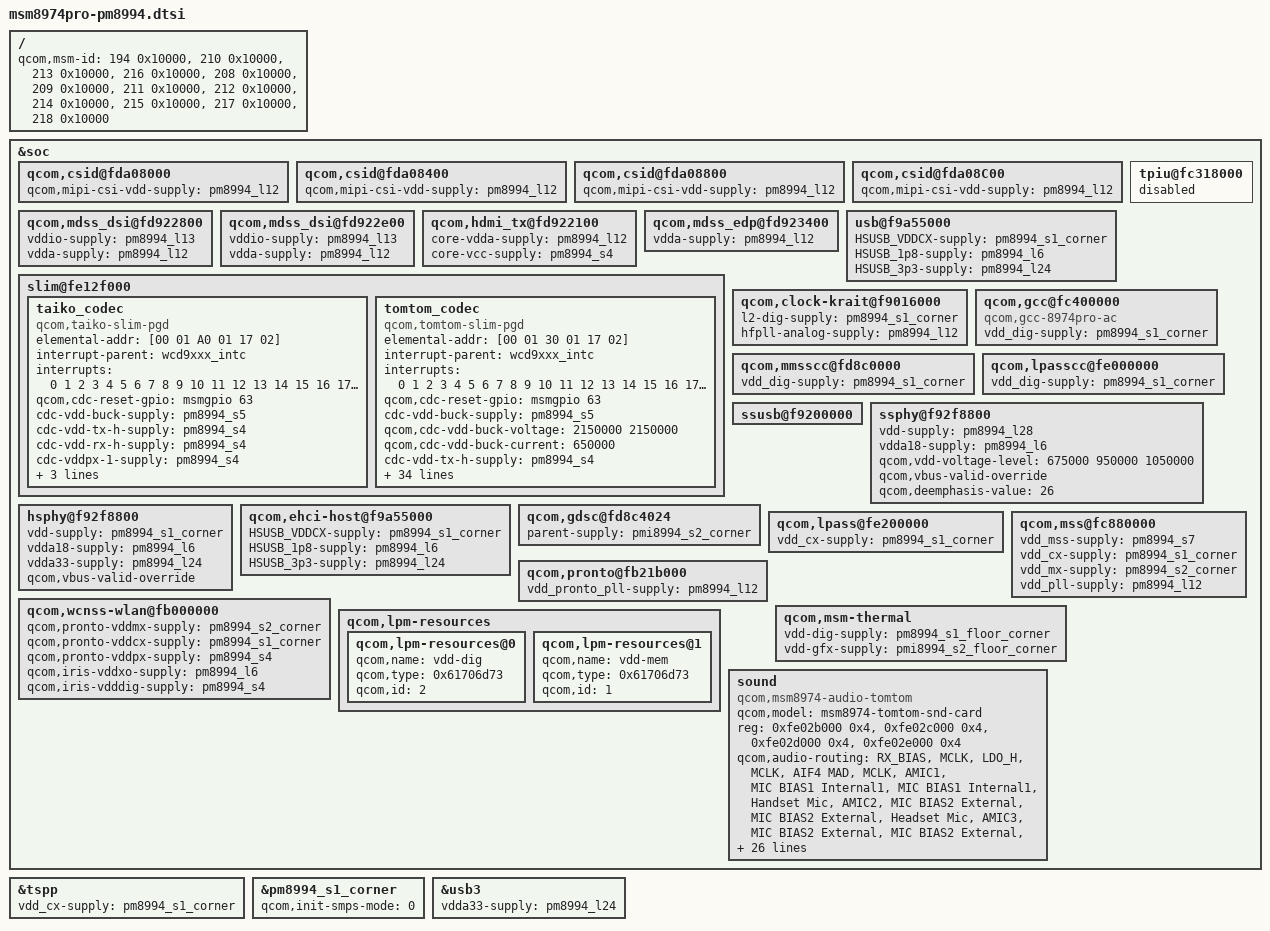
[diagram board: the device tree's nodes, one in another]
/* Copyright (c) 2013-2015, The Linux Foundation. All rights reserved.
 *
 * This program is free software; you can redistribute it and/or modify
 * it under the terms of the GNU General Public License version 2 and
 * only version 2 as published by the Free Software Foundation.
 *
 * This program is distributed in the hope that it will be useful,
 * but WITHOUT ANY WARRANTY; without even the implied warranty of
 * MERCHANTABILITY or FITNESS FOR A PARTICULAR PURPOSE.  See the
 * GNU General Public License for more details.
 */

/*
 * As a general rule, only chipset-specific property overrides should be placed
 * inside this file. However, device definitions should be placed inside the
 * msm8974.dtsi / msm8974pro.dtsi file(s).
 */

#include "msm8974pro.dtsi"
#include "msm-pm8994.dtsi"
#include "msm-pmi8994.dtsi"
#include "msm-pm8994-rpm-regulator.dtsi"
#include "msm8994-regulator.dtsi"

/ {
	qcom,msm-id = <194 0x10000>,
		      <210 0x10000>,
		      <213 0x10000>,
		      <216 0x10000>,
		      <208 0x10000>,
		      <209 0x10000>,
		      <211 0x10000>,
		      <212 0x10000>,
		      <214 0x10000>,
		      <215 0x10000>,
		      <217 0x10000>,
		      <218 0x10000>;
};

/*
 * Override PM8841 and PM8941 resources with proper PM8994 resources for
 * MSM8994 Interposer.
 */

&soc {
	qcom,csid@fda08000  {
		qcom,mipi-csi-vdd-supply = <&pm8994_l12>;
	};

	qcom,csid@fda08400 {
		qcom,mipi-csi-vdd-supply = <&pm8994_l12>;
	};

	qcom,csid@fda08800 {
		qcom,mipi-csi-vdd-supply = <&pm8994_l12>;
	};

	qcom,csid@fda08C00 {
		qcom,mipi-csi-vdd-supply = <&pm8994_l12>;
	};

	tpiu@fc318000 {
		status = "disabled";
		/delete-property/ vdd-supply;
		/delete-property/ vdd-io-supply;
	};

	qcom,mdss_dsi@fd922800 {
		vddio-supply = <&pm8994_l13>;
		vdda-supply = <&pm8994_l12>;
		/delete-property/ qcom,platform-reset-gpio;
		/delete-property/ vdd-supply;
	};

	qcom,mdss_dsi@fd922e00 {
		vddio-supply = <&pm8994_l13>;
		vdda-supply = <&pm8994_l12>;
		/delete-property/ qcom,platform-reset-gpio;
		/delete-property/ vdd-supply;
	};

	qcom,hdmi_tx@fd922100 {
		core-vdda-supply = <&pm8994_l12>;
		core-vcc-supply = <&pm8994_s4>;
		/delete-property/ hpd-5v-supply;
	};

	qcom,mdss_edp@fd923400 {
		vdda-supply = <&pm8994_l12>;
	};

	usb@f9a55000 {
		HSUSB_VDDCX-supply = <&pm8994_s2_corner>;
		HSUSB_1p8-supply = <&pm8994_l6>;
		HSUSB_3p3-supply = <&pm8994_l24>;
	};

	slim@fe12f000 {
		taiko_codec {
			compatible = "qcom,taiko-slim-pgd";
			elemental-addr = [00 01 A0 01 17 02];

			interrupt-parent = <&wcd9xxx_intc>;
			interrupts = <0 1 2 3 4 5 6 7 8 9 10 11 12 13 14 15 16
				      17 18 19 20 21 22 23 24 25 26 27 28>;

			qcom,cdc-reset-gpio = <&msmgpio 63 0>;

			cdc-vdd-buck-supply = <&pm8994_s5>;
			cdc-vdd-tx-h-supply = <&pm8994_s4>;
			cdc-vdd-rx-h-supply = <&pm8994_s4>;
			cdc-vddpx-1-supply = <&pm8994_s4>;
			/* TODO: this is supplied by DBU whatever that means */
			cdc-vdd-a-1p2v-supply = <&pm8994_l11>;
			cdc-vddcx-1-supply = <&pm8994_l11>;
			cdc-vddcx-2-supply = <&pm8994_l11>;
		};

		tomtom_codec {
			compatible = "qcom,tomtom-slim-pgd";
			elemental-addr = [00 01 30 01 17 02];

			interrupt-parent = <&wcd9xxx_intc>;
			interrupts = <0 1 2 3 4 5 6 7 8 9 10 11 12 13 14 15 16
				      17 18 19 20 21 22 23 24 25 26 27 28 30 31>;

			qcom,cdc-reset-gpio = <&msmgpio 63 0>;

			cdc-vdd-buck-supply = <&pm8994_s5>;
			qcom,cdc-vdd-buck-voltage = <2150000 2150000>;
			qcom,cdc-vdd-buck-current = <650000>;

			cdc-vdd-tx-h-supply = <&pm8994_s4>;
			qcom,cdc-vdd-tx-h-voltage = <1800000 1800000>;
			qcom,cdc-vdd-tx-h-current = <25000>;

			cdc-vdd-rx-h-supply = <&pm8994_s4>;
			qcom,cdc-vdd-rx-h-voltage = <1800000 1800000>;
			qcom,cdc-vdd-rx-h-current = <25000>;

			cdc-vddpx-1-supply = <&pm8994_s4>;
			qcom,cdc-vddpx-1-voltage = <1800000 1800000>;
			qcom,cdc-vddpx-1-current = <10000>;

			cdc-vdd-a-1p2v-supply = <&pm8994_l11>;
			qcom,cdc-vdd-a-1p2v-voltage = <1200000 1200000>;
			qcom,cdc-vdd-a-1p2v-current = <2000>;

			cdc-vddcx-1-supply = <&pm8994_l11>;
			qcom,cdc-vddcx-1-voltage = <1200000 1200000>;
			qcom,cdc-vddcx-1-current = <33000>;

			cdc-vddcx-2-supply = <&pm8994_l11>;
			qcom,cdc-vddcx-2-voltage = <1200000 1200000>;
			qcom,cdc-vddcx-2-current = <33000>;

			qcom,cdc-static-supplies = "cdc-vdd-buck",
						   "cdc-vdd-tx-h",
						   "cdc-vdd-rx-h",
						   "cdc-vddpx-1",
						   "cdc-vdd-a-1p2v",
						   "cdc-vddcx-1",
						   "cdc-vddcx-2";

			qcom,cdc-micbias-ldoh-v = <0x3>;
			qcom,cdc-micbias-cfilt1-mv = <1800>;
			qcom,cdc-micbias-cfilt2-mv = <2700>;
			qcom,cdc-micbias-cfilt3-mv = <1800>;
			qcom,cdc-micbias1-cfilt-sel = <0x0>;
			qcom,cdc-micbias2-cfilt-sel = <0x1>;
			qcom,cdc-micbias3-cfilt-sel = <0x2>;
			qcom,cdc-micbias4-cfilt-sel = <0x2>;
			qcom,cdc-mclk-clk-rate = <9600000>;
			qcom,cdc-slim-ifd = "tomtom-slim-ifd";
			qcom,cdc-slim-ifd-elemental-addr = [00 00 30 01 17 02];
			qcom,cdc-dmic-sample-rate = <4800000>;
			qcom,cdc-variant = "WCD9330";
		};
	};

	qcom,clock-krait@f9016000 {
		l2-dig-supply = <&pm8994_s1_corner>;
		/* TODO once RPM reg change adds device below
		 * hfpll-dig-supply = <&pm8994_s1_corner_ao>;
		 */
		/delete-property/ hfpll-dig-supply;
		/delete-property/ cpu0-supply;
		/delete-property/ cpu1-supply;
		/delete-property/ cpu2-supply;
		/delete-property/ cpu3-supply;
		hfpll-analog-supply = <&pm8994_l12>;
	};

	qcom,gcc@fc400000 {
		compatible = "qcom,gcc-8974pro-ac";
		vdd_dig-supply = <&pm8994_s1_corner>;
	};

	qcom,mmsscc@fd8c0000 {
		vdd_dig-supply = <&pm8994_s1_corner>;
	};

	qcom,lpasscc@fe000000 {
		vdd_dig-supply = <&pm8994_s1_corner>;
	};

	usb@f9a55000 {
		HSUSB_VDDCX-supply = <&pm8994_s1_corner>;
		HSUSB_1p8-supply = <&pm8994_l6>;
		HSUSB_3p3-supply = <&pm8994_l24>;
	};

	ssusb@f9200000 {
		/delete-property/ vbus_dwc3-supply;
		/delete-property/ qcom,misc-ref;
		/delete-property/ dwc_usb3-adc_tm;
	};

	ssphy@f92f8800 {
		vdd-supply = <&pm8994_l28>;
		vdda18-supply = <&pm8994_l6>;
		qcom,vdd-voltage-level = <675000 950000 1050000>;
		qcom,vbus-valid-override;
		qcom,deemphasis-value = <26>;
	};

	hsphy@f92f8800 {
		vdd-supply = <&pm8994_s1_corner>;
		vdda18-supply = <&pm8994_l6>;
		vdda33-supply = <&pm8994_l24>;
		qcom,vbus-valid-override;
	};

	qcom,ehci-host@f9a55000 {
		HSUSB_VDDCX-supply = <&pm8994_s1_corner>;
		HSUSB_1p8-supply = <&pm8994_l6>;
		HSUSB_3p3-supply = <&pm8994_l24>;
	};

	qcom,gdsc@fd8c4024 {
		parent-supply = <&pmi8994_s2_corner>;
	};

	qcom,lpass@fe200000 {
		vdd_cx-supply = <&pm8994_s1_corner>;
	};

	qcom,mss@fc880000 {
		vdd_mss-supply = <&pm8994_s7>;
		vdd_cx-supply = <&pm8994_s1_corner>;
		vdd_mx-supply = <&pm8994_s2_corner>;
		vdd_pll-supply = <&pm8994_l12>;
	};

	qcom,pronto@fb21b000 {
		vdd_pronto_pll-supply = <&pm8994_l12>;
	};

	qcom,wcnss-wlan@fb000000 {
		qcom,pronto-vddmx-supply = <&pm8994_s2_corner>;
		qcom,pronto-vddcx-supply = <&pm8994_s1_corner>;
		qcom,pronto-vddpx-supply = <&pm8994_s4>;
		qcom,iris-vddxo-supply = <&pm8994_l6>;
		/delete-property/ qcom,iris-vddrfa-supply;
		/delete-property/ qcom,iris-vddpa-supply;
		qcom,iris-vdddig-supply = <&pm8994_s4>;
	};

	qcom,msm-thermal {
		vdd-dig-supply = <&pm8994_s1_floor_corner>;
		vdd-gfx-supply = <&pmi8994_s2_floor_corner>;
		/delete-property/ qcom,pmic-sw-mode-temp;
		/delete-property/ qcom,pmic-sw-mode-temp-hysteresis;
		/delete-property/ qcom,pmic-sw-mode-regs;
	};

	qcom,lpm-resources {
		qcom,lpm-resources@0 {
			qcom,name = "vdd-dig";
			qcom,type = <0x61706d73>;	/* "smpa" */
			qcom,id = <2>;
		};

		qcom,lpm-resources@1 {
			qcom,name = "vdd-mem";
			qcom,type = <0x61706d73>;	/* "smpa" */
			qcom,id = <1>;
		};
	};

	sound {
		compatible = "qcom,msm8974-audio-tomtom";
		qcom,model = "msm8974-tomtom-snd-card";
		reg = <0xfe02b000 0x4>,
		      <0xfe02c000 0x4>,
		      <0xfe02d000 0x4>,
		      <0xfe02e000 0x4>;
		reg-names = "lpaif_pri_mode_muxsel",
			    "lpaif_sec_mode_muxsel",
			    "lpaif_tert_mode_muxsel",
			    "lpaif_quat_mode_muxsel";

		qcom,audio-routing =
			"RX_BIAS", "MCLK",
			"LDO_H", "MCLK",
			"AIF4 MAD", "MCLK",
			"AMIC1", "MIC BIAS1 Internal1",
			"MIC BIAS1 Internal1", "Handset Mic",
			"AMIC2", "MIC BIAS2 External",
			"MIC BIAS2 External", "Headset Mic",
			"AMIC3", "MIC BIAS2 External",
			"MIC BIAS2 External", "ANCRight Headset Mic",
			"AMIC4", "MIC BIAS2 External",
			"MIC BIAS2 External", "ANCLeft Headset Mic",
			"DMIC1", "MIC BIAS1 External",
			"MIC BIAS1 External", "Digital Mic1",
			"DMIC2", "MIC BIAS1 External",
			"MIC BIAS1 External", "Digital Mic2",
			"DMIC3", "MIC BIAS3 External",
			"MIC BIAS3 External", "Digital Mic3",
			"DMIC4", "MIC BIAS3 External",
			"MIC BIAS3 External", "Digital Mic4",
			"DMIC5", "MIC BIAS4 External",
			"MIC BIAS4 External", "Digital Mic5",
			"DMIC6", "MIC BIAS4 External",
			"MIC BIAS4 External", "Digital Mic6";

		qcom,cdc-mclk-gpios = <&pm8994_gpios 15 0>;
		qcom,tomtom-mclk-clk-freq = <9600000>;
		qcom,prim-auxpcm-gpio-clk  = <&msmgpio 65 0>;
		qcom,prim-auxpcm-gpio-sync = <&msmgpio 66 0>;
		qcom,prim-auxpcm-gpio-din  = <&msmgpio 67 0>;
		qcom,prim-auxpcm-gpio-dout = <&msmgpio 68 0>;
		qcom,prim-auxpcm-gpio-set = "prim-gpio-prim";
		qcom,sec-auxpcm-gpio-clk  = <&msmgpio 79 0>;
		qcom,sec-auxpcm-gpio-sync = <&msmgpio 80 0>;
		qcom,sec-auxpcm-gpio-din  = <&msmgpio 81 0>;
		qcom,sec-auxpcm-gpio-dout = <&msmgpio 82 0>;
		qcom,cdc-micbias2-headset-only;
		qcom,us-euro-gpios = <&pm8994_mpps 2 0>;
		qcom,mbhc-audio-jack-type = "6-pole-jack";
	};
};

&tspp {
	vdd_cx-supply = <&pm8994_s1_corner>;
};

&pm8994_s1_corner {
	qcom,init-smps-mode = <0>;	/* Allow AUTO mode for VDD_CX. */
};

&usb3 {
	vdda33-supply = <&pm8994_l24>;
};
